# RL6845_IP_SVD register map
Vendor: Realtek
Registers are 32-bit, read-write, reset 0x0 unless marked. A register's access mark holds for its fields unless they carry their own. Offsets are from the block's base; [hi:lo] are bit positions; lines under a group give offsets from that group; {n}, {i} and the like mark numbered series.

## memx
Base 0x41008600
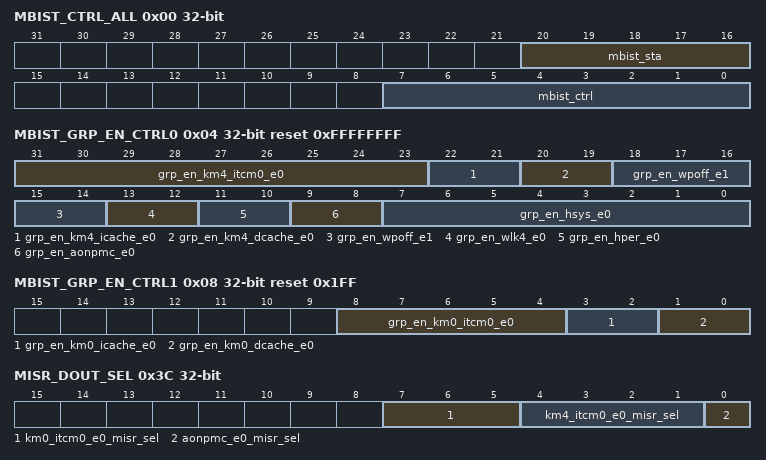
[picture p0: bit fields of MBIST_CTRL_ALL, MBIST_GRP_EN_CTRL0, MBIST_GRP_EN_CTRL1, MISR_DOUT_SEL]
0x00 MBIST_CTRL_ALL access per field — MEMx MBIST control and status register
  [20:16] mbist_sta ro — Total mbist status [16] MBIST DRF_START_PAUSE [17] MBIST NRML_DONE_ALL [18] MBIST NRML_FAIL_ALL [19] MBIST DRF_DONE_ALL [20] MBIST DRF_FAIL_ALL
  [7:0] mbist_ctrl rw — Total mbist control [0] MBIST_CLK_EN_ALL BIS_CLK enable of all system memory groups. [1] MBIST_RSTB_ALL Reset controll mbist circuit of all system memory groups. [3:2]MBIST_MSEL_ALL mbist method selection of all memory groups: 2'b01: enable normal mode mbist 2'b10: enable DRF mode mbist 2'b11: enable normal&DRF mode mbist [4]MBIST_RESUME [5]MBIST_RESUME_PS [6]MBIST_DYN_READ_EN If MBIST_MSEL_ALL[1]=1 & MBIST_DYN_READ_EN=1, run VDDR mode mbist. 7]MBIST_PHYCLK_STOP
0x04 MBIST_GRP_EN_CTRL0 reset 0xFFFFFFFF — Used to on-off mbist of memory block in a group.
  [31:23] grp_en_km4_itcm0_e0, [22:21] grp_en_km4_icache_e0, [20:19] grp_en_km4_dcache_e0, [18:14] grp_en_wpoff_e1, [13:12] grp_en_wlk4_e0, [11:10] grp_en_hper_e0, [9:8] grp_en_aonpmc_e0, [7:0] grp_en_hsys_e0
0x08 MBIST_GRP_EN_CTRL1 reset 0x1FF — Used to on-off mbist of memory block in a group.
  [8:4] grp_en_km0_itcm0_e0, [3:2] grp_en_km0_icache_e0, [1:0] grp_en_km0_dcache_e0
0x0C MBIST_GRP_EN_BT_VIR_E00 reset 0xFFFFF
  [19:0] bt_vir_e0_bist_en_19_0
0x10 MBIST_DONE_STA0 ro
  [21:0] mbist_done_21_0
0x14 MBIST_START_PULSE0 ro
  [21:0] mbist_start_pause_21_0
0x18 MBIST_NORM_FAIL0 ro
  [31:0] mbist_norm_fail_31_0
0x1C MBIST_NORM_FAIL1 ro
  [20:0] mbist_norm_fail_52_32
0x20 MBIST_DRF_FAIL0 ro
  [31:0] mbist_drf_fail_31_0
0x24 MBIST_DRF_FAIL1 ro
  [20:0] mbist_drf_fail_52_32
0x28 BT_VIR_E0_BIST_DONE0 ro
  [19:0] bt_vir_e0_mbist_done_19_0
0x2C BT_VIR_E0_BIST_FAIL0 ro
  [19:0] bt_vir_e0_mbist_fail_19_0
0x30 BT_VIR_E0_BIST_DRF_PAUSE0 ro
  [19:0] bt_vir_e0_mbist_drf_pause_19_0
0x34 BT_VIR_E0_BIST_RPT ro
0x38 BT_VIR_E0_RPT_SEL
  [3:0] bt_vir_e0_rpt_sel — Select which rom's misr_dataout or bist_status of each memory can be read from bt_vir_e0_bist_rpt
0x3C MISR_DOUT_SEL
  [7:5] km0_itcm0_e0_misr_sel, [4:1] km4_itcm0_e0_misr_sel, [0] aonpmc_e0_misr_sel
0x40 LSPMC_E0_ROM_MISR0 ro
  [31:0] lspmc_e0_misr_dout_31_0
0x44 LSPMC_E0_ROM_MISR1 ro
  [3:0] lspmc_e0_misr_dout_35_32
0x48 AONPMC_E0_ROM_MISR1 ro
  [31:0] aonpmc_e0_misr_dout_31_0
0x4C AONPMC_E0_ROM_MISR2 ro
  [3:0] aonpmc_e0_misr_dout_35_32
0x50 KM4_ITCM0_E0_ROM_MISR2 ro
  [31:0] km4_itcm0_e0_misr_dout_31_0
0x54 KM4_ITCM0_E0_ROM_MISR3 ro
  [31:0] km4_itcm0_e0_misr_dout_63_32
0x58 KM0_ITCM0_E0_ROM_MISR3 ro
  [31:0] km0_itcm0_e0_misr_dout_31_0
0x5C KM0_ITCM0_E0_ROM_MISR4 ro
  [31:0] km0_itcm0_e0_misr_dout_63_32
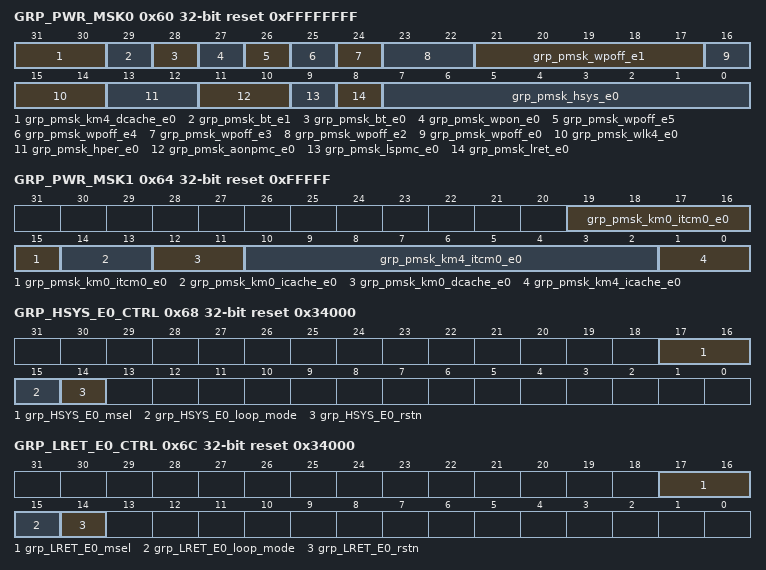
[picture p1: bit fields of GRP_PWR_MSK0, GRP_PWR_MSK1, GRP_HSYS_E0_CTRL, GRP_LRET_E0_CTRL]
0x60 GRP_PWR_MSK0 reset 0xFFFFFFFF
  [31:30] grp_pmsk_km4_dcache_e0, [29] grp_pmsk_bt_e1, [28] grp_pmsk_bt_e0, [27] grp_pmsk_wpon_e0, [26] grp_pmsk_wpoff_e5, [25] grp_pmsk_wpoff_e4, [24] grp_pmsk_wpoff_e3, [23:22] grp_pmsk_wpoff_e2, [21:17] grp_pmsk_wpoff_e1, [16] grp_pmsk_wpoff_e0, [15:14] grp_pmsk_wlk4_e0, [13:12] grp_pmsk_hper_e0, [11:10] grp_pmsk_aonpmc_e0, [9] grp_pmsk_lspmc_e0, [8] grp_pmsk_lret_e0, [7:0] grp_pmsk_hsys_e0
0x64 GRP_PWR_MSK1 reset 0xFFFFF
  [19:15] grp_pmsk_km0_itcm0_e0, [14:13] grp_pmsk_km0_icache_e0, [12:11] grp_pmsk_km0_dcache_e0, [10:2] grp_pmsk_km4_itcm0_e0, [1:0] grp_pmsk_km4_icache_e0
0x68 GRP_HSYS_E0_CTRL reset 0x34000
  [17:16] grp_HSYS_E0_msel — *01 - This memory group can do normal mbist; *10 - This memory group can do DRF mbist; *11 - This memory group can do normal & DRF mbist
  [15] grp_HSYS_E0_loop_mode — *0 - Assist loop mode; *1 - Don't assist loop mode
  [14] grp_HSYS_E0_rstn — *0 - Reset mbist circuit of this memory group; *1 - Release mbist circuit of this memory group.
0x6C GRP_LRET_E0_CTRL reset 0x34000
  [17:16] grp_LRET_E0_msel — *01 - This memory group can do normal mbist; *10 - This memory group can do DRF mbist; *11 - This memory group can do normal & DRF mbist
  [15] grp_LRET_E0_loop_mode — *0 - Assist loop mode; *1 - Don't assist loop mode
  [14] grp_LRET_E0_rstn — *0 - Reset mbist circuit of this memory group; *1 - Release mbist circuit of this memory group.
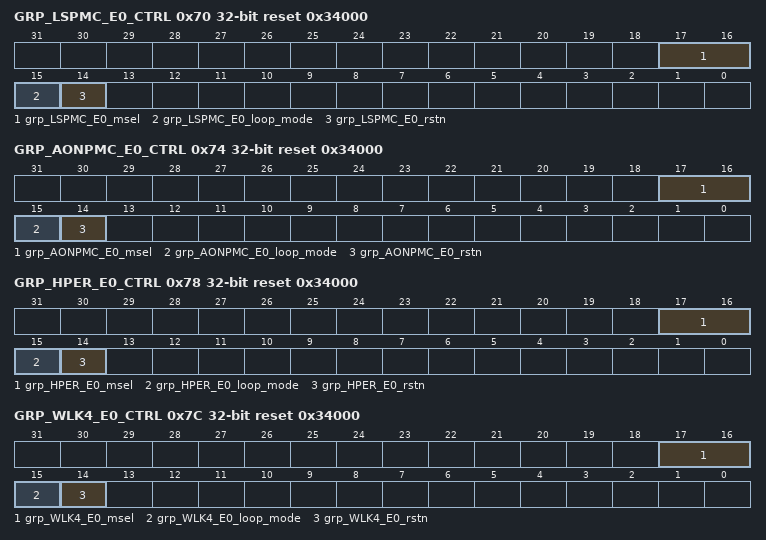
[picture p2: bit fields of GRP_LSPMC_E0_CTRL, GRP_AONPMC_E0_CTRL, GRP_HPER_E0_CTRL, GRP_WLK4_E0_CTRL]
0x70 GRP_LSPMC_E0_CTRL reset 0x34000
  [17:16] grp_LSPMC_E0_msel — *01 - This memory group can do normal mbist; *10 - This memory group can do DRF mbist; *11 - This memory group can do normal & DRF mbist
  [15] grp_LSPMC_E0_loop_mode — *0 - Assist loop mode; *1 - Don't assist loop mode
  [14] grp_LSPMC_E0_rstn — *0 - Reset mbist circuit of this memory group; *1 - Release mbist circuit of this memory group.
0x74 GRP_AONPMC_E0_CTRL reset 0x34000
  [17:16] grp_AONPMC_E0_msel — *01 - This memory group can do normal mbist; *10 - This memory group can do DRF mbist; *11 - This memory group can do normal & DRF mbist
  [15] grp_AONPMC_E0_loop_mode — *0 - Assist loop mode; *1 - Don't assist loop mode
  [14] grp_AONPMC_E0_rstn — *0 - Reset mbist circuit of this memory group; *1 - Release mbist circuit of this memory group.
0x78 GRP_HPER_E0_CTRL reset 0x34000
  [17:16] grp_HPER_E0_msel — *01 - This memory group can do normal mbist; *10 - This memory group can do DRF mbist; *11 - This memory group can do normal & DRF mbist
  [15] grp_HPER_E0_loop_mode — *0 - Assist loop mode; *1 - Don't assist loop mode
  [14] grp_HPER_E0_rstn — *0 - Reset mbist circuit of this memory group; *1 - Release mbist circuit of this memory group.
0x7C GRP_WLK4_E0_CTRL reset 0x34000
  [17:16] grp_WLK4_E0_msel — *01 - This memory group can do normal mbist; *10 - This memory group can do DRF mbist; *11 - This memory group can do normal & DRF mbist
  [15] grp_WLK4_E0_loop_mode — *0 - Assist loop mode; *1 - Don't assist loop mode
  [14] grp_WLK4_E0_rstn — *0 - Reset mbist circuit of this memory group; *1 - Release mbist circuit of this memory group.
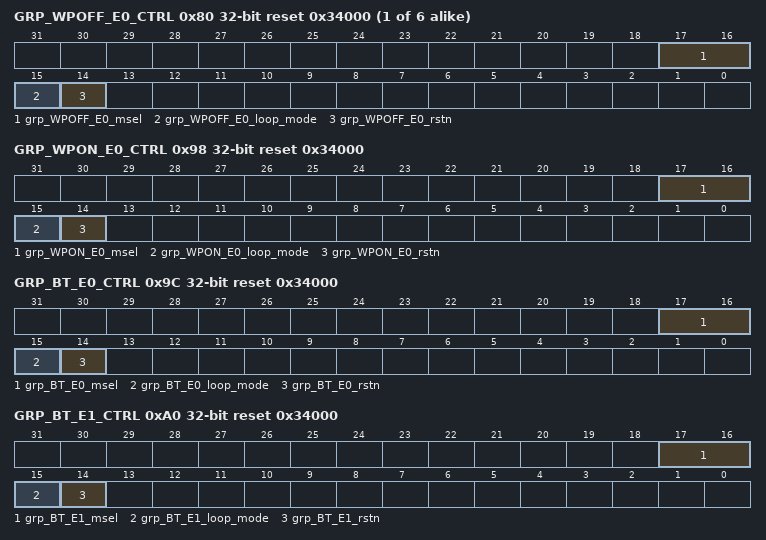
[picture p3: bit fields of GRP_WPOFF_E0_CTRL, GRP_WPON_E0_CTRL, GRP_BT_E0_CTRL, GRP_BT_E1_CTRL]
{0x80+4i} GRP_WPOFF_E{i}_CTRL reset 0x34000 (i=0..5)
  [17:16] grp_WPOFF_E{i}_msel — *01 - This memory group can do normal mbist; *10 - This memory group can do DRF mbist; *11 - This memory group can do normal & DRF mbist
  [15] grp_WPOFF_E{i}_loop_mode — *0 - Assist loop mode; *1 - Don't assist loop mode
  [14] grp_WPOFF_E{i}_rstn — *0 - Reset mbist circuit of this memory group; *1 - Release mbist circuit of this memory group.
0x98 GRP_WPON_E0_CTRL reset 0x34000
  [17:16] grp_WPON_E0_msel — *01 - This memory group can do normal mbist; *10 - This memory group can do DRF mbist; *11 - This memory group can do normal & DRF mbist
  [15] grp_WPON_E0_loop_mode — *0 - Assist loop mode; *1 - Don't assist loop mode
  [14] grp_WPON_E0_rstn — *0 - Reset mbist circuit of this memory group; *1 - Release mbist circuit of this memory group.
0x9C GRP_BT_E0_CTRL reset 0x34000
  [17:16] grp_BT_E0_msel — *01 - This memory group can do normal mbist; *10 - This memory group can do DRF mbist; *11 - This memory group can do normal & DRF mbist
  [15] grp_BT_E0_loop_mode — *0 - Assist loop mode; *1 - Don't assist loop mode
  [14] grp_BT_E0_rstn — *0 - Reset mbist circuit of this memory group; *1 - Release mbist circuit of this memory group.
0xA0 GRP_BT_E1_CTRL reset 0x34000
  [17:16] grp_BT_E1_msel — *01 - This memory group can do normal mbist; *10 - This memory group can do DRF mbist; *11 - This memory group can do normal & DRF mbist
  [15] grp_BT_E1_loop_mode — *0 - Assist loop mode; *1 - Don't assist loop mode
  [14] grp_BT_E1_rstn — *0 - Reset mbist circuit of this memory group; *1 - Release mbist circuit of this memory group.
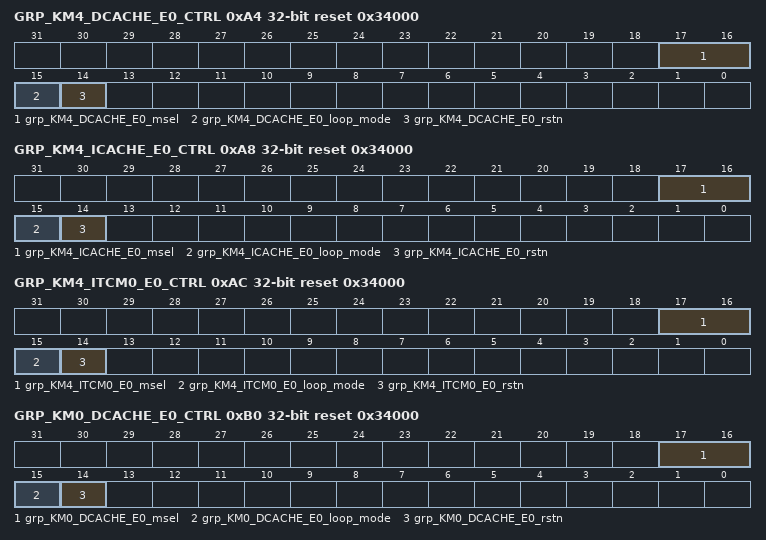
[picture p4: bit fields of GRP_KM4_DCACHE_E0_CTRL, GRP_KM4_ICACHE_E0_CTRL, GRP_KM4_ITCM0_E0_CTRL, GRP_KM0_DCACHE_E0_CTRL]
0xA4 GRP_KM4_DCACHE_E0_CTRL reset 0x34000
  [17:16] grp_KM4_DCACHE_E0_msel — *01 - This memory group can do normal mbist; *10 - This memory group can do DRF mbist; *11 - This memory group can do normal & DRF mbist
  [15] grp_KM4_DCACHE_E0_loop_mode — *0 - Assist loop mode; *1 - Don't assist loop mode
  [14] grp_KM4_DCACHE_E0_rstn — *0 - Reset mbist circuit of this memory group; *1 - Release mbist circuit of this memory group.
0xA8 GRP_KM4_ICACHE_E0_CTRL reset 0x34000
  [17:16] grp_KM4_ICACHE_E0_msel — *01 - This memory group can do normal mbist; *10 - This memory group can do DRF mbist; *11 - This memory group can do normal & DRF mbist
  [15] grp_KM4_ICACHE_E0_loop_mode — *0 - Assist loop mode; *1 - Don't assist loop mode
  [14] grp_KM4_ICACHE_E0_rstn — *0 - Reset mbist circuit of this memory group; *1 - Release mbist circuit of this memory group.
0xAC GRP_KM4_ITCM0_E0_CTRL reset 0x34000
  [17:16] grp_KM4_ITCM0_E0_msel — *01 - This memory group can do normal mbist; *10 - This memory group can do DRF mbist; *11 - This memory group can do normal & DRF mbist
  [15] grp_KM4_ITCM0_E0_loop_mode — *0 - Assist loop mode; *1 - Don't assist loop mode
  [14] grp_KM4_ITCM0_E0_rstn — *0 - Reset mbist circuit of this memory group; *1 - Release mbist circuit of this memory group.
0xB0 GRP_KM0_DCACHE_E0_CTRL reset 0x34000
  [17:16] grp_KM0_DCACHE_E0_msel — *01 - This memory group can do normal mbist; *10 - This memory group can do DRF mbist; *11 - This memory group can do normal & DRF mbist
  [15] grp_KM0_DCACHE_E0_loop_mode — *0 - Assist loop mode; *1 - Don't assist loop mode
  [14] grp_KM0_DCACHE_E0_rstn — *0 - Reset mbist circuit of this memory group; *1 - Release mbist circuit of this memory group.
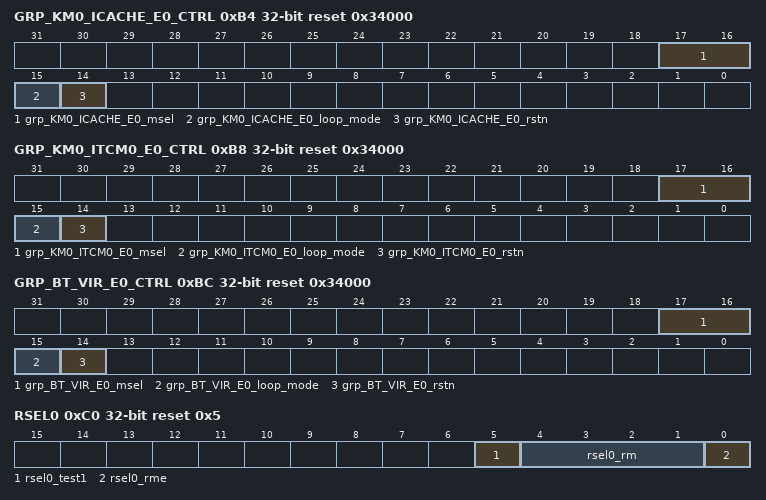
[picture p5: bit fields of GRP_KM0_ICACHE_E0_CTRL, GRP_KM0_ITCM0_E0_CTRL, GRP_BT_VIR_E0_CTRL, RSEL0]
0xB4 GRP_KM0_ICACHE_E0_CTRL reset 0x34000
  [17:16] grp_KM0_ICACHE_E0_msel — *01 - This memory group can do normal mbist; *10 - This memory group can do DRF mbist; *11 - This memory group can do normal & DRF mbist
  [15] grp_KM0_ICACHE_E0_loop_mode — *0 - Assist loop mode; *1 - Don't assist loop mode
  [14] grp_KM0_ICACHE_E0_rstn — *0 - Reset mbist circuit of this memory group; *1 - Release mbist circuit of this memory group.
0xB8 GRP_KM0_ITCM0_E0_CTRL reset 0x34000
  [17:16] grp_KM0_ITCM0_E0_msel — *01 - This memory group can do normal mbist; *10 - This memory group can do DRF mbist; *11 - This memory group can do normal & DRF mbist
  [15] grp_KM0_ITCM0_E0_loop_mode — *0 - Assist loop mode; *1 - Don't assist loop mode
  [14] grp_KM0_ITCM0_E0_rstn — *0 - Reset mbist circuit of this memory group; *1 - Release mbist circuit of this memory group.
0xBC GRP_BT_VIR_E0_CTRL reset 0x34000
  [17:16] grp_BT_VIR_E0_msel — *01 - This memory group can do normal mbist; *10 - This memory group can do DRF mbist; *11 - This memory group can do normal & DRF mbist
  [15] grp_BT_VIR_E0_loop_mode — *0 - Assist loop mode; *1 - Don't assist loop mode
  [14] grp_BT_VIR_E0_rstn — *0 - Reset mbist circuit of this memory group; *1 - Release mbist circuit of this memory group.
0xC0 RSEL0 reset 0x5
  [5] rsel0_test1, [4:1] rsel0_rm, [0] rsel0_rme
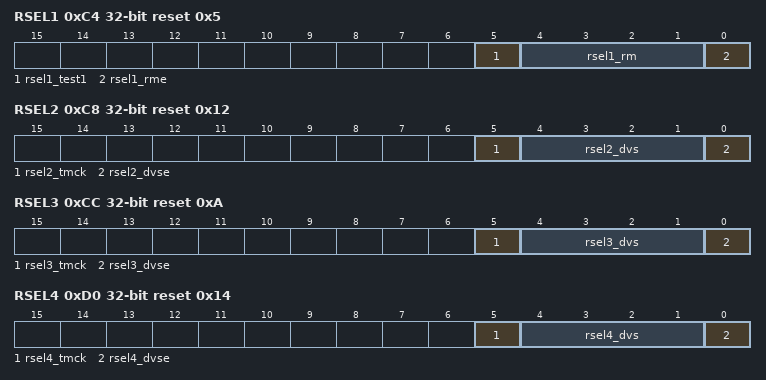
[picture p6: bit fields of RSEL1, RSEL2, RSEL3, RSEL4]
0xC4 RSEL1 reset 0x5
  [5] rsel1_test1, [4:1] rsel1_rm, [0] rsel1_rme
0xC8 RSEL2 reset 0x12
  [5] rsel2_tmck, [4:1] rsel2_dvs, [0] rsel2_dvse
0xCC RSEL3 reset 0xA
  [5] rsel3_tmck, [4:1] rsel3_dvs, [0] rsel3_dvse
0xD0 RSEL4 reset 0x14
  [5] rsel4_tmck, [4:1] rsel4_dvs, [0] rsel4_dvse
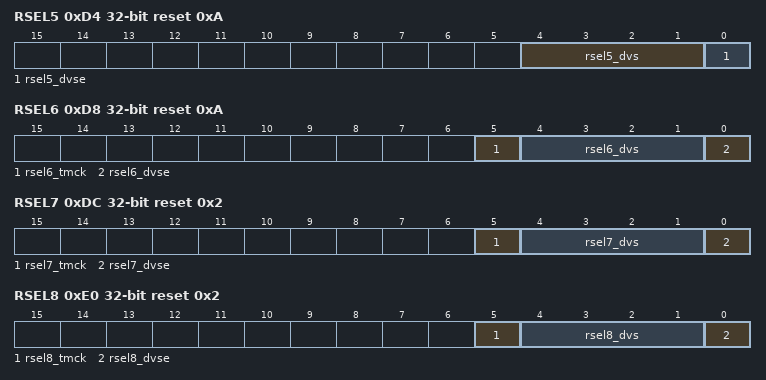
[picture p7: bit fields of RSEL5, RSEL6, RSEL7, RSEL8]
0xD4 RSEL5 reset 0xA
  [4:1] rsel5_dvs, [0] rsel5_dvse
0xD8 RSEL6 reset 0xA
  [5] rsel6_tmck, [4:1] rsel6_dvs, [0] rsel6_dvse
0xDC RSEL7 reset 0x2
  [5] rsel7_tmck, [4:1] rsel7_dvs, [0] rsel7_dvse
0xE0 RSEL8 reset 0x2
  [5] rsel8_tmck, [4:1] rsel8_dvs, [0] rsel8_dvse
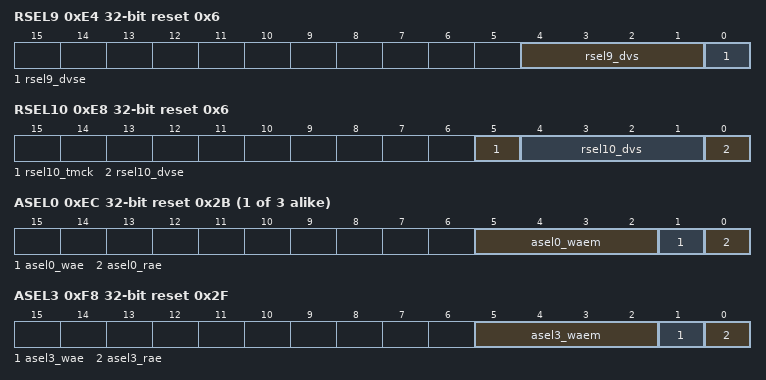
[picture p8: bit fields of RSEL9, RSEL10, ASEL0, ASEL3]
0xE4 RSEL9 reset 0x6
  [4:1] rsel9_dvs, [0] rsel9_dvse
0xE8 RSEL10 reset 0x6
  [5] rsel10_tmck, [4:1] rsel10_dvs, [0] rsel10_dvse
{0xEC+4i} ASEL{i} reset 0x2B (i=0..2)
  [5:2] asel{i}_waem, [1] asel{i}_wae, [0] asel{i}_rae
0xF8 ASEL3 reset 0x2F
  [5:2] asel3_waem, [1] asel3_wae, [0] asel3_rae
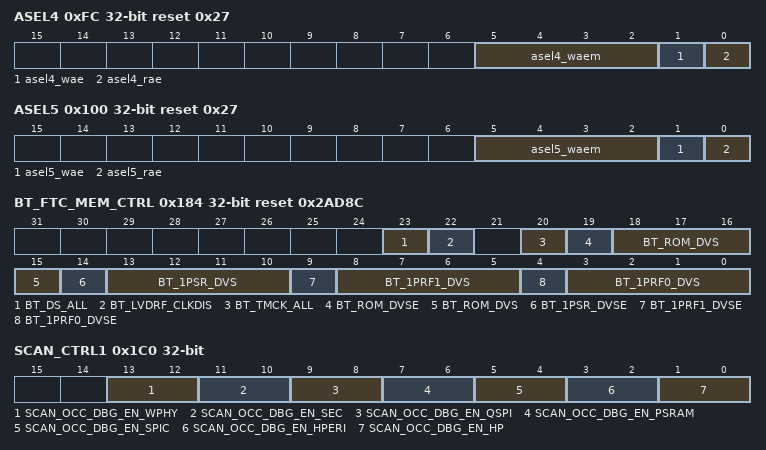
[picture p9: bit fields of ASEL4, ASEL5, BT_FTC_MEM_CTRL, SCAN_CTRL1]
0xFC ASEL4 reset 0x27
  [5:2] asel4_waem, [1] asel4_wae, [0] asel4_rae
0x100 ASEL5 reset 0x27
  [5:2] asel5_waem, [1] asel5_wae, [0] asel5_rae
0x184 BT_FTC_MEM_CTRL reset 0x2AD8C
  [23] BT_DS_ALL — 1 - All BT memory switch to Deep Sleep mode 0 - Power mode of BT memory are controlled by BTPMC
  [22] BT_LVDRF_CLKDIS
  [20] BT_TMCK_ALL
  [19] BT_ROM_DVSE
  [18:15] BT_ROM_DVS — FSNOU_A_SPNN
  [14] BT_1PSR_DVSE — Not used in Lite
  [13:10] BT_1PSR_DVS — Not used in Lite
  [9] BT_1PRF1_DVSE
  [8:5] BT_1PRF1_DVS — FSNOU_A_SYNL
  [4] BT_1PRF0_DVSE
  [3:0] BT_1PRF0_DVS — FSNOU_A_SYNL
0x1C0 SCAN_CTRL1
  [13:12] SCAN_OCC_DBG_EN_WPHY, [11:10] SCAN_OCC_DBG_EN_SEC, [9:8] SCAN_OCC_DBG_EN_QSPI, [7:6] SCAN_OCC_DBG_EN_PSRAM, [5:4] SCAN_OCC_DBG_EN_SPIC, [3:2] SCAN_OCC_DBG_EN_HPERI, [1:0] SCAN_OCC_DBG_EN_HP
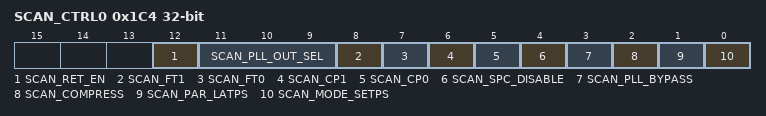
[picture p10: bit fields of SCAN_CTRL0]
0x1C4 SCAN_CTRL0 access per field
  [12] SCAN_RET_EN rw — scan retention test enable
  [11:9] SCAN_PLL_OUT_SEL rw
  [8] SCAN_FT1 rw — scan ft mode1
  [7] SCAN_FT0 rw — scan ft mode0
  [6] SCAN_CP1 rw — scan cp mode1/cp_ret
  [5] SCAN_CP0 rw — scan cp mode0
  [4] SCAN_SPC_DISABLE rw
  [3] SCAN_PLL_BYPASS rw
  [2] SCAN_COMPRESS rw
  [1] SCAN_PAR_LATPS rw — Used as scan latch enable bit . If want to change scan par from func setting , set this bit to 1 first , then write func register will also effect scan shadow register .
  [0] SCAN_MODE_SETPS wo — scan mode pulse
0x1FC Dummy reset 0xFF00
  [15:0] dummy
